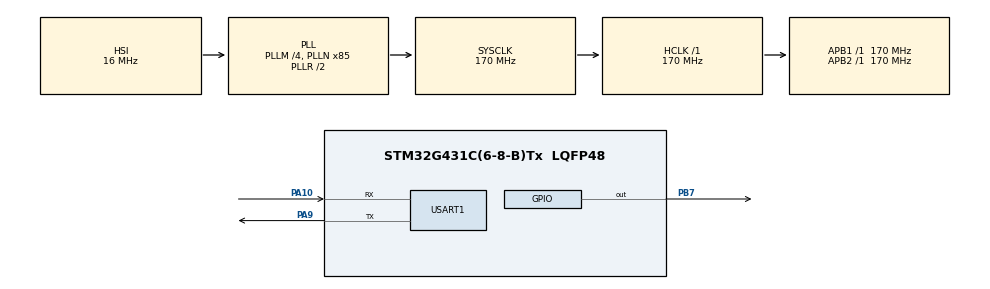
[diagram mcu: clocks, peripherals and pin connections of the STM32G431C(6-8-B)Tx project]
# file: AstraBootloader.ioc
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Mcu.Family=STM32G4
Mcu.Name=STM32G431C(6-8-B)Tx
Mcu.Package=LQFP48
NVIC.PriorityGroup=NVIC_PRIORITYGROUP_4
NVIC.USART1_IRQn=true\:0\:0\:false\:false\:true\:true\:true\:true
PA10.Mode=Asynchronous
PA10.Signal=USART1_RX
PA9.Mode=Asynchronous
PA9.Signal=USART1_TX
PB7.Signal=GPIO_Output
PC14-OSC32_IN.Mode=LSE-External-Oscillator
PC14-OSC32_IN.Signal=RCC_OSC32_IN
PC15-OSC32_OUT.Mode=LSE-External-Oscillator
PC15-OSC32_OUT.Signal=RCC_OSC32_OUT
PF0-OSC_IN.Mode=HSE-External-Oscillator
PF0-OSC_IN.Signal=RCC_OSC_IN
PF1-OSC_OUT.Mode=HSE-External-Oscillator
PF1-OSC_OUT.Signal=RCC_OSC_OUT
ProjectManager.HeapSize=0x200
ProjectManager.StackSize=0x400
ProjectManager.TargetToolchain=CMake
RCC.ADC12Freq_Value=170000000
RCC.AHBFreq_Value=170000000
RCC.APB1Freq_Value=170000000
RCC.APB1TimFreq_Value=170000000
RCC.APB2Freq_Value=170000000
RCC.APB2TimFreq_Value=170000000
RCC.CortexFreq_Value=170000000
RCC.EXTERNAL_CLOCK_VALUE=12288000
RCC.HCLKFreq_Value=170000000
RCC.HSE_VALUE=8000000
RCC.HSI48_VALUE=48000000
RCC.HSI_VALUE=16000000
RCC.PLLM=RCC_PLLM_DIV4
RCC.PLLN=85
RCC.SYSCLKFreq_VALUE=170000000
RCC.SYSCLKSource=RCC_SYSCLKSOURCE_PLLCLK
RCC.USBFreq_Value=170000000
RCC.VCOOutputFreq_Value=340000000
USART1.VirtualMode-Asynchronous=VM_ASYNC
VP_SYS_VS_DBSignals.Mode=DisableDeadBatterySignals
board=custom

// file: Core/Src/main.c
/* USER CODE BEGIN Header */
/**
  ******************************************************************************
  * @file           : main.c
  * @brief          : Main program body
  ******************************************************************************
  * @attention
  *
  * Copyright (c) 2026 STMicroelectronics.
  * All rights reserved.
  *
  * This software is licensed under terms that can be found in the LICENSE file
  * in the root directory of this software component.
  * If no LICENSE file comes with this software, it is provided AS-IS.
  *
  ******************************************************************************
  */
/* USER CODE END Header */
#include "main.h"

/* USER CODE BEGIN Includes */
#include "BootloaderJump.h"
#include "BootloaderOta.h"
/* USER CODE END Includes */

UART_HandleTypeDef huart1;

void SystemClock_Config(void);
static void MX_GPIO_Init(void);
static void MX_USART1_UART_Init(void);

int main(void)
{

  /* MCU Configuration--------------------------------------------------------*/

  /* Reset of all peripherals, Initializes the Flash interface and the Systick. */
  HAL_Init();

  /* Configure the system clock */
  SystemClock_Config();

  /* USER CODE BEGIN SysInit */
  /* Link diagnostic: sample USART1 RX before the UART claims the pin. */
  bool const rxLineHigh = BootloaderOta_SniffRxLine();
  /* USER CODE END SysInit */

  /* Initialize all configured peripherals */
  MX_GPIO_Init();
  MX_USART1_UART_Init();
  /* USER CODE BEGIN 2 */

  /* Start listening immediately: the handover from the application may already
   * have pushed bytes into the receiver, and an unread byte plus overrun would
   * turn the first interrupt into an error that stops reception. */
  BootloaderOta_PrimeRx(&huart1);

  /* Link diagnostic: 3 fast blinks = USART1 RX idles high, so the bridge is
   * wired and driving; 1 fast blink = the line is low (wire, pad or bridge TX).
   * Then the four one-second blinks mark "bootloader is entering OTA mode". */
  for (uint32_t i = 0U; i < (rxLineHigh ? 3U : 1U); i++)
  {
      HAL_GPIO_TogglePin(GPIOB, GPIO_PIN_7);
      HAL_Delay(150);
      HAL_GPIO_TogglePin(GPIOB, GPIO_PIN_7);
      HAL_Delay(250);
  }

  for (uint32_t blink = 0U; blink <= 3U; blink++)
  {
      HAL_GPIO_TogglePin(GPIOB, GPIO_PIN_7);
      HAL_Delay(1000);
  }

  if (IsApplicationValid() != APPLICATION_VALID || BootloaderOta_IsRequested())
  {
    /* Returns only when the listen window expires and the application is
     * valid.  After a successful update this resets the MCU. */
    BootloaderOta_Run(&huart1);
  }

  if (IsApplicationValid() == APPLICATION_VALID)
  {
    JumpToApplication();
  }
  /* USER CODE END 2 */

  /* Infinite loop */
  while (1)
  {

  }
}

void SystemClock_Config(void)
{
  RCC_OscInitTypeDef RCC_OscInitStruct = {0};
  RCC_ClkInitTypeDef RCC_ClkInitStruct = {0};

  /** Configure the main internal regulator output voltage
  */
  HAL_PWREx_ControlVoltageScaling(PWR_REGULATOR_VOLTAGE_SCALE1_BOOST);

  /** Initializes the RCC Oscillators according to the specified parameters
  * in the RCC_OscInitTypeDef structure.
  */
  RCC_OscInitStruct.OscillatorType = RCC_OSCILLATORTYPE_HSI;
  RCC_OscInitStruct.HSIState = RCC_HSI_ON;
  RCC_OscInitStruct.HSICalibrationValue = RCC_HSICALIBRATION_DEFAULT;
  RCC_OscInitStruct.PLL.PLLState = RCC_PLL_ON;
  RCC_OscInitStruct.PLL.PLLSource = RCC_PLLSOURCE_HSI;
  RCC_OscInitStruct.PLL.PLLM = RCC_PLLM_DIV4;
  RCC_OscInitStruct.PLL.PLLN = 85;
  RCC_OscInitStruct.PLL.PLLP = RCC_PLLP_DIV2;
  RCC_OscInitStruct.PLL.PLLQ = RCC_PLLQ_DIV2;
  RCC_OscInitStruct.PLL.PLLR = RCC_PLLR_DIV2;
  if (HAL_RCC_OscConfig(&RCC_OscInitStruct) != HAL_OK)
  {
    Error_Handler();
  }

  /** Initializes the CPU, AHB and APB buses clocks
  */
  RCC_ClkInitStruct.ClockType = RCC_CLOCKTYPE_HCLK|RCC_CLOCKTYPE_SYSCLK
                              |RCC_CLOCKTYPE_PCLK1|RCC_CLOCKTYPE_PCLK2;
  RCC_ClkInitStruct.SYSCLKSource = RCC_SYSCLKSOURCE_PLLCLK;
  RCC_ClkInitStruct.AHBCLKDivider = RCC_SYSCLK_DIV1;
  RCC_ClkInitStruct.APB1CLKDivider = RCC_HCLK_DIV1;
  RCC_ClkInitStruct.APB2CLKDivider = RCC_HCLK_DIV1;

  if (HAL_RCC_ClockConfig(&RCC_ClkInitStruct, FLASH_LATENCY_4) != HAL_OK)
  {
    Error_Handler();
  }
}

static void MX_USART1_UART_Init(void)
{

  huart1.Instance = USART1;
  huart1.Init.BaudRate = 115200;
  huart1.Init.WordLength = UART_WORDLENGTH_8B;
  huart1.Init.StopBits = UART_STOPBITS_1;
  huart1.Init.Parity = UART_PARITY_NONE;
  huart1.Init.Mode = UART_MODE_TX_RX;
  huart1.Init.HwFlowCtl = UART_HWCONTROL_NONE;
  huart1.Init.OverSampling = UART_OVERSAMPLING_16;
  huart1.Init.OneBitSampling = UART_ONE_BIT_SAMPLE_DISABLE;
  huart1.Init.ClockPrescaler = UART_PRESCALER_DIV1;
  huart1.AdvancedInit.AdvFeatureInit = UART_ADVFEATURE_NO_INIT;
  if (HAL_UART_Init(&huart1) != HAL_OK)
  {
    Error_Handler();
  }
  if (HAL_UARTEx_SetTxFifoThreshold(&huart1, UART_TXFIFO_THRESHOLD_1_8) != HAL_OK)
  {
    Error_Handler();
  }
  if (HAL_UARTEx_SetRxFifoThreshold(&huart1, UART_RXFIFO_THRESHOLD_1_8) != HAL_OK)
  {
    Error_Handler();
  }
  if (HAL_UARTEx_DisableFifoMode(&huart1) != HAL_OK)
  {
    Error_Handler();
  }

}

static void MX_GPIO_Init(void)
{
  GPIO_InitTypeDef GPIO_InitStruct = {0};

  /* GPIO Ports Clock Enable */
  __HAL_RCC_GPIOC_CLK_ENABLE();
  __HAL_RCC_GPIOF_CLK_ENABLE();
  __HAL_RCC_GPIOA_CLK_ENABLE();
  __HAL_RCC_GPIOB_CLK_ENABLE();

  /*Configure GPIO pin Output Level */
  HAL_GPIO_WritePin(GPIOB, GPIO_PIN_7, GPIO_PIN_RESET);

  /*Configure GPIO pin : PB7 */
  GPIO_InitStruct.Pin = GPIO_PIN_7;
  GPIO_InitStruct.Mode = GPIO_MODE_OUTPUT_PP;
  GPIO_InitStruct.Pull = GPIO_NOPULL;
  GPIO_InitStruct.Speed = GPIO_SPEED_FREQ_LOW;
  HAL_GPIO_Init(GPIOB, &GPIO_InitStruct);

  /* USER CODE BEGIN MX_GPIO_Init_2 */
  /* Link diagnostic: PB9 latches on when the first byte arrives from the
   * bridge, so RX activity is visible without any PC-side tooling. */
  HAL_GPIO_WritePin(GPIOB, GPIO_PIN_9, GPIO_PIN_RESET);
  GPIO_InitStruct.Pin = GPIO_PIN_9;
  GPIO_InitStruct.Mode = GPIO_MODE_OUTPUT_PP;
  GPIO_InitStruct.Pull = GPIO_NOPULL;
  GPIO_InitStruct.Speed = GPIO_SPEED_FREQ_LOW;
  HAL_GPIO_Init(GPIOB, &GPIO_InitStruct);
  /* USER CODE END MX_GPIO_Init_2 */
}

/* USER CODE BEGIN 4 */
void HAL_UART_RxCpltCallback(UART_HandleTypeDef *huart)
{
    if (huart->Instance == USART1)
    {
        BootloaderOta_OnRxCplt(huart);
    }
}

void HAL_UART_ErrorCallback(UART_HandleTypeDef *huart)
{
    if (huart->Instance == USART1)
    {
        BootloaderOta_OnError(huart);
    }
}
/* USER CODE END 4 */

void Error_Handler(void)
{
  __disable_irq();
  while (1)
  {
  }
}
